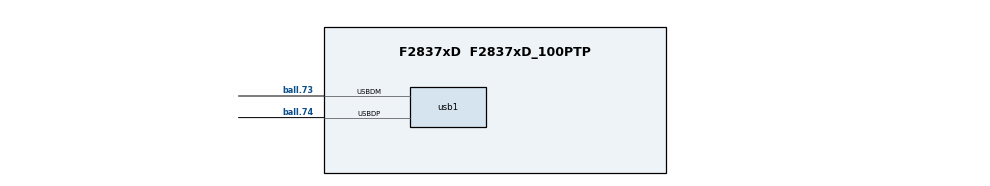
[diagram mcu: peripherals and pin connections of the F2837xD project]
/**
 * @cliArgs --device "F2837xD" --package "F2837xD_100PTP" --part "F2837xD_100PTP" --product "C2000WARE@4.02.00.00"
 * @versions {"tool":"1.13.0+2411"}
 */

/**
 * Import the modules used in this configuration.
 */
const usb  = scripting.addModule("/driverlib/usb.js", {}, false);
const usb1 = usb.addInstance();

/**
 * Write custom configuration values to the imported modules.
 */
usb1.$name                  = "myUSB0";
usb1.registerInterrupts     = true;
usb1.usb.usbdmPin.$assign   = "ball.73";
usb1.usb.usbdpPin.$assign   = "ball.74";
usb1.dmQual.$name           = "myGPIOQUAL0";
usb1.dpQual.$name           = "myGPIOQUAL1";
usb1.pfltQual.$name         = "myGPIOQUAL2";
usb1.epenQual.$name         = "myGPIOQUAL3";
usb1.USBInt.enableInterrupt = true;

/**
 * Pinmux solution for unlocked pins/peripherals. This ensures that minor changes to the automatic solver in a future
 * version of the tool will not impact the pinmux you originally saw.  These lines can be completely deleted in order to
 * re-solve from scratch.
 */
usb1.usb.$suggestSolution = "USB0";
